# ATSAML11E16A register map
Vendor: Microchip Technology; Series: SAML11; File version: 0
CPU: CM23 r0p0, selectable endian, MPU, no FPU, 2 interrupt priority bits
Registers are 32-bit, read-write, reset 0x0 unless marked. A register's access mark holds for its fields unless they carry their own. Offsets are from the block's base; [hi:lo] are bit positions; lines under a group give offsets from that group; {n}, {i} and the like mark numbered series; 'fields as' and 'values as' point back to an identical list.

## PORT — Port Module
Base 0x40003000; register names take the prefix PORT_
Same registers: PORT_SEC 0x40003200 (register names take the prefix PORT_SEC_), PORT_IOBUS 0x60000000 (register names take the prefix PORT_IOBUS_), PORT_IOBUS_SEC 0x60000200 (register names take the prefix PORT_IOBUS_SEC_)
{0x0+0x80*i} GROUP[{i}] (i=0..0) group
  0x00 DIR — Data Direction
    [31:0] DIR — Port Data Direction
  0x04 DIRCLR — Data Direction Clear
    [31:0] DIRCLR — Port Data Direction Clear
  0x08 DIRSET — Data Direction Set
    [31:0] DIRSET — Port Data Direction Set
  0x0C DIRTGL — Data Direction Toggle
    [31:0] DIRTGL — Port Data Direction Toggle
  0x10 OUT — Data Output Value
    [31:0] OUT — PORT Data Output Value
  0x14 OUTCLR — Data Output Value Clear
    [31:0] OUTCLR — PORT Data Output Value Clear
  0x18 OUTSET — Data Output Value Set
    [31:0] OUTSET — PORT Data Output Value Set
  0x1C OUTTGL — Data Output Value Toggle
    [31:0] OUTTGL — PORT Data Output Value Toggle
  0x20 IN ro — Data Input Value
    [31:0] IN — PORT Data Input Value
  0x24 CTRL — Control
    [31:0] SAMPLING — Input Sampling Mode
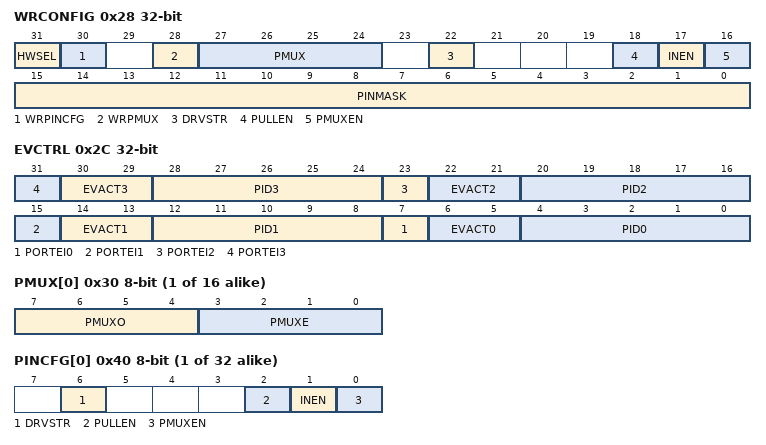
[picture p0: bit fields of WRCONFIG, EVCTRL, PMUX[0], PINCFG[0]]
  0x28 WRCONFIG wo — Write Configuration
    [31] HWSEL — Half-Word Select
    [30] WRPINCFG — Write PINCFG
    [28] WRPMUX — Write PMUX
    [27:24] PMUX — Peripheral Multiplexing
    [22] DRVSTR — Output Driver Strength Selection
    [18] PULLEN — Pull Enable
    [17] INEN — Input Enable
    [16] PMUXEN — Peripheral Multiplexer Enable
    [15:0] PINMASK — Pin Mask for Multiple Pin Configuration
  0x2C EVCTRL — Event Input Control
    [8n+7] PORTEI{n} (n=0..3) — PORT Event Input Enable {n}
    [30:29] EVACT3 — PORT Event Action 3
    [8n+4:8n] PID{n} (n=0..3) — PORT Event Pin Identifier {n}
    [22:21] EVACT2 — PORT Event Action 2
    [14:13] EVACT1 — PORT Event Action 1
    [6:5] EVACT0 — PORT Event Action 0
      0=OUT (Event output to pin); 1=SET (Set output register of pin on event); 2=CLR (Clear output register of pin on event); 3=TGL (Toggle output register of pin on event)
  {0x30+j} PMUX[{j}] (j=0..15) 8-bit — Peripheral Multiplexing
    [7:4] PMUXO — Peripheral Multiplexing for Odd-Numbered Pin
    [3:0] PMUXE — Peripheral Multiplexing for Even-Numbered Pin
  {0x40+j} PINCFG[{j}] (j=0..31) 8-bit — Pin Configuration
    [6] DRVSTR — Output Driver Strength Selection
    [2] PULLEN — Pull Enable
    [1] INEN — Input Enable
    [0] PMUXEN — Peripheral Multiplexer Enable
  0x60 INTENCLR — Interrupt Enable Clear
    [0] NSCHK — Non-Secure Check Interrupt Enable
  0x64 INTENSET — Interrupt Enable Set
    [0] NSCHK — Non-Secure Check Interrupt Enable
  0x68 INTFLAG — Interrupt Flag Status and Clear
    [0] NSCHK — Non-Secure Check
  0x6C NONSEC — Security Attribution
    [31:0] NONSEC — Port Security Attribution
  0x70 NSCHK — Security Attribution Check
    [31:0] NSCHK — Port Security Attribution Check

## PTC — Peripheral Touch Controller
Base 0x42002400; register names take the prefix PTC_

## RSTC — Reset Controller
Base 0x40000C00; register names take the prefix RSTC_
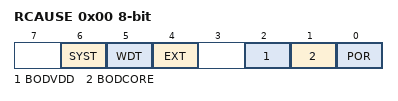
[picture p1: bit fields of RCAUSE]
0x00 RCAUSE 8-bit ro — Reset Cause
  [6] SYST — System Reset Request
  [5] WDT — Watchdog Reset
  [4] EXT — External Reset
  [2] BODVDD — Brown Out VDD Detector Reset
  [1] BODCORE — Brown Out CORE Detector Reset
  [0] POR — Power On Reset

## TRAM — TrustRAM
Base 0x42003400; register names take the prefix TRAM_
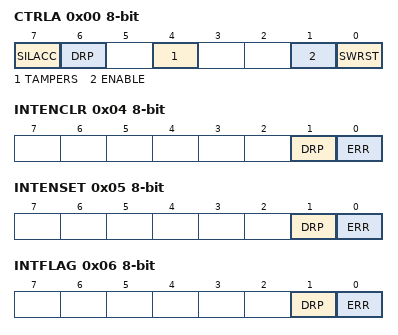
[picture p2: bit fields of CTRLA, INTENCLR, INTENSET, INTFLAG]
0x00 CTRLA 8-bit — Control
  [7] SILACC — Silent Access
  [6] DRP — Data Remanence Prevention
  [4] TAMPERS — Tamper Erase
  [1] ENABLE
  [0] SWRST — Software Reset
0x04 INTENCLR 8-bit — Interrupt Enable Clear
  [1] DRP — Data Remanence Prevention Ended Interrupt Enable
  [0] ERR — TrustRAM Readout Error Interrupt Enable
0x05 INTENSET 8-bit — Interrupt Enable Set
  fields as INTENCLR
0x06 INTFLAG 8-bit — Interrupt Flag Status and Clear
  [1] DRP — Data Remanence Prevention Ended
  [0] ERR — TrustRAM Readout Error
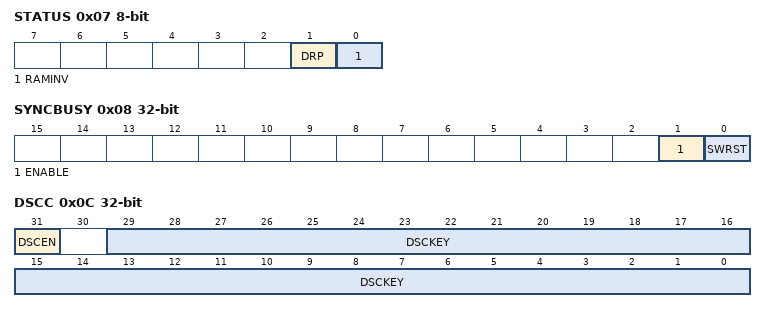
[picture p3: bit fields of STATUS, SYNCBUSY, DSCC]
0x07 STATUS 8-bit ro
  [1] DRP — Data Remanence Prevention Ongoing
  [0] RAMINV — RAM Inversion Bit
0x08 SYNCBUSY ro — Synchronization Busy Status
  [1] ENABLE — Enable Busy
  [0] SWRST — Software Reset Busy
0x0C DSCC wo — Data Scramble Control
  [31] DSCEN — Data Scramble Enable
  [29:0] DSCKEY — Data Scramble Key
0x10 PERMW 8-bit wo — Permutation Write
  [2:0] DATA — Permutation Scrambler Data Input
0x11 PERMR 8-bit ro — Permutation Read
  [2:0] DATA — Permutation Scrambler Data Output
{0x100+4i} RAM[{i}] (i=0..63) — TrustRAM
  [31:0] DATA — Trust RAM Data
